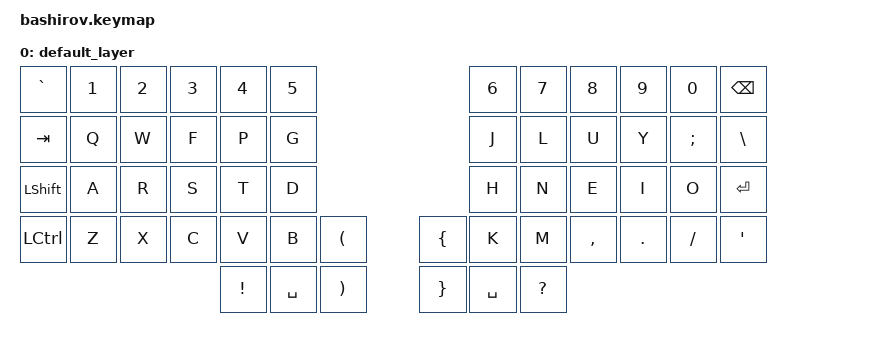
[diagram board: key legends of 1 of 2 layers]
#include <behaviors.dtsi>
#include <dt-bindings/zmk/keys.h>
#include <dt-bindings/zmk/bt.h>

/ {
        keymap {
                compatible = "zmk,keymap";

                default_layer {
// ---------------------------------------------------------------------------------
// |   `  |  1  |  2  |  3  |  4  |  9  |     |  6  |  7  |  8  |  9  |  0  -----------| BKSP |
// |  TAB |  Q  |  W  |  F  |  P  |  G  |     |  J  |  U  |  Y  |  ;  |  P  |  \   |
// | CAPS |  A  |  R  |  S  |  T  |  D  |     |  N  |  E  |  I  |  O  |  ;  |  ENT |
// | SHFT |  Z  |  X  |  C  |  V  |  B  |     |  K  |  M  |  ,  |  .  |  /  | APOS |
// | CTRL | ALT | GUI | SPC | SPC | SPC |     | SPC | LOW |LARW |DARW |UARW | RARW |
                        bindings = <
   &kp GRAVE  &kp N1    &kp N2    &kp N3     &kp N4     &kp N5               		  &kp N6     &kp N7  &kp N8     &kp N9    &kp N0    &kp BSPC
   &kp TAB    &kp Q     &kp W     &kp F      &kp P      &kp G                		  &kp J      &kp L   &kp U      &kp Y     &kp SEMI  &kp BSLH
   &kp LSHIFT &kp A     &kp R     &kp S      &kp T      &kp D                		  &kp H      &kp N   &kp E      &kp I     &kp O     &kp RET
   &kp LCTRL  &kp Z     &kp X     &kp C      &kp V      &kp B	    &kp LPAR	&kp LBRC  &kp K      &kp M   &kp COMMA  &kp DOT   &kp FSLH  &kp APOS
   					     &kp EXCL   &kp SPACE   &kp RPAR    &kp RBRC  &kp SPACE  &kp QMARK
                        >;
                };
                lower_layer {
// ------------------------------------------------------------------------------------------------------------
// |       |  BT1  |  BT2  |  BT3  |  BT4  |  BT5  |          |       |       |       |       |       | BTCLR |
// |       |       |       |       |       |       |          |       |       |       |       |       |       |
// |       |       |       | LPAR  | RPAR  |       |          |       | LBKT  | RBKT  |       |       |       |
// |       |       |       |       |       |       |          |       |       |       |       |       |       |
                        bindings = <
   &trans    &bt BT_SEL 0   &bt BT_SEL 1   &bt BT_SEL 2   &bt BT_SEL 3   &bt BT_SEL 4           &trans    &trans    &trans   &trans   &trans  &bt BT_CLR
   &trans    &trans         &trans         &trans         &trans         &trans                 &trans    &trans    &trans   &trans   &trans  &trans
   &trans    &trans         &trans         &kp LPAR       &kp RPAR       &trans                 &trans    &kp LBKT  &kp RBKT &kp MINUS   &kp EQUAL  &trans
   &trans    &trans         &trans         &trans         &trans         &trans                 &trans    &trans    &trans   &trans   &trans  &trans
                        >;
                };
        };
};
